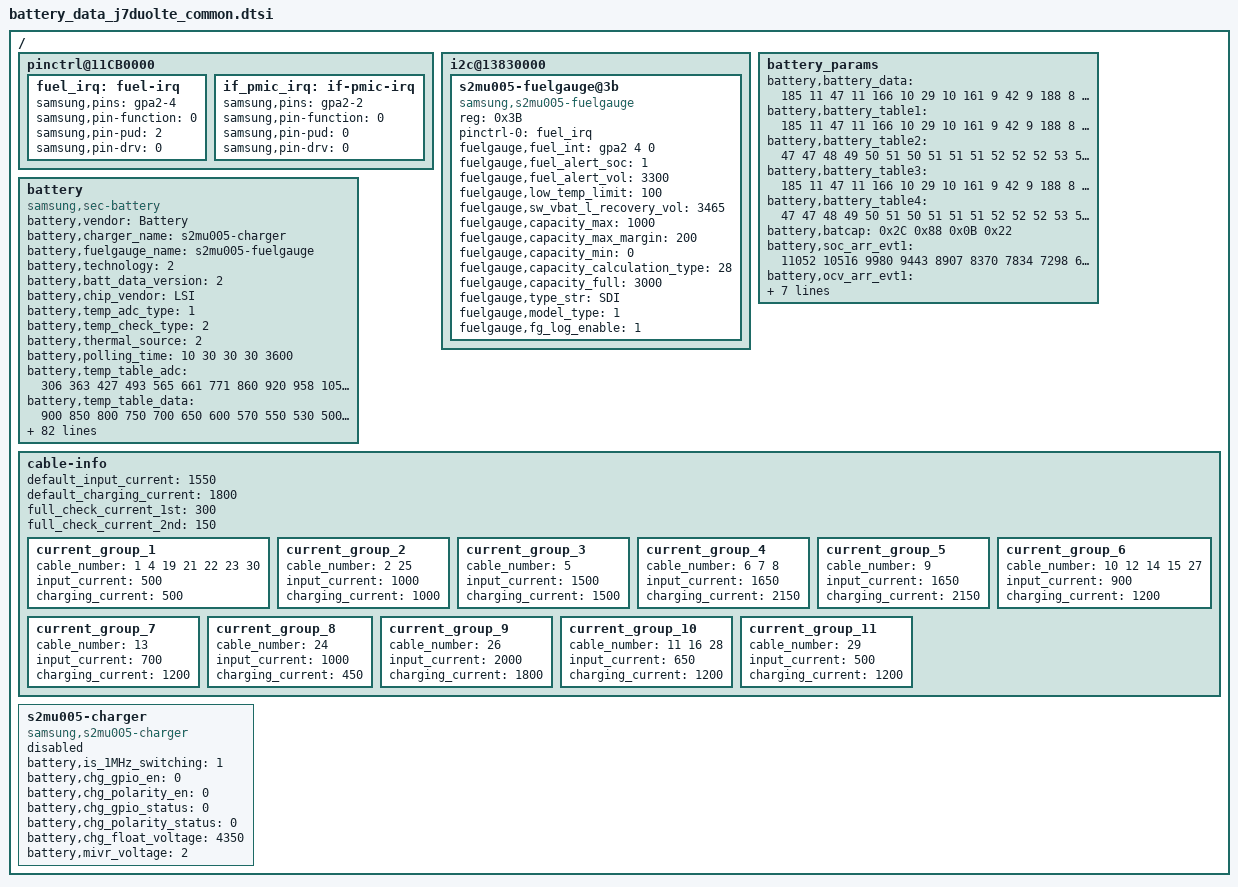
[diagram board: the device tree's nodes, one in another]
/*
 * J7 TOP Battery parameters device tree file for board IDs 04 and higher
 *
 * Copyright (C) 2017 Samsung Electronics, Inc.
 *
 * This program is free software; you can redistribute it and/or
 * modify it under the terms of the GNU General Public License
 * as published by the Free Software Foundation; either version 2
 * of the License, or (at your option) any later version.
 *
 * This program is distributed in the hope that it will be useful,
 * but WITHOUT ANY WARRANTY; without even the implied warranty of
 * MERCHANTABILITY or FITNESS FOR A PARTICULAR PURPOSE.  See the
 * GNU General Public License for more details.
 *
 * You should have received a copy of the GNU General Public License
 * along with this program. If not, see <http://www.gnu.org/licenses/>.
 *
 */

/ {
	pinctrl@11CB0000 {
		fuel_irq: fuel-irq {
			samsung,pins = "gpa2-4";
			samsung,pin-function = <0>;
			samsung,pin-pud = <2>;
			samsung,pin-drv = <0>;
		};

		if_pmic_irq: if-pmic-irq {
			samsung,pins = "gpa2-2";
			samsung,pin-function = <0>;
			samsung,pin-pud = <0>;
			samsung,pin-drv = <0>;
		};
	};

	i2c@13830000 {
		status = "okay";
		s2mu005-fuelgauge@3b {
			compatible = "samsung,s2mu005-fuelgauge";
			reg = <0x3B>;
			pinctrl-names = "default";
			pinctrl-0 = <&fuel_irq>;
			fuelgauge,fuel_int = <&gpa2 4 0>;
			fuelgauge,fuel_alert_soc = <1>;
			fuelgauge,fuel_alert_vol = <3300>;
			fuelgauge,low_temp_limit = <100>;
			fuelgauge,sw_vbat_l_recovery_vol = <3465>;
			fuelgauge,capacity_max = <1000>;
			fuelgauge,capacity_max_margin = <200>;
			fuelgauge,capacity_min = <0>;
			fuelgauge,capacity_calculation_type = <28>;
			fuelgauge,capacity_full = <3000>;
			fuelgauge,type_str = "SDI";
			fuelgauge,model_type = <1>;
			fuelgauge,fg_log_enable = <1>;
		};
	};

	battery_params {
		battery,battery_data =
			<
			/***** battery data for 4.35 *****/
			/* battery,battery_table3 */
			185 11 47 11 166 10 29 10 161 9
			42 9 188 8 87 8 230 7 155 7
			64 7 222 6 161 6 119 6 86 6
			62 6 42 6 5 6 190 5 143 5
			55 5 242 1 215 8 106 8 252 7
			142 7 32 7 178 6 68 6 215 5
			105 5 251 4 141 4 31 4 177 3
			67 3 214 2 104 2 250 1 140 1
			30 1 176 0 66 0 213 15
			
			/* battery,battery_table4 */
			47 47 48 49 50 51 50 51 51 51
			52 52 52 53 53 54 54 55 56 57
			60 150
			
			/* battery,batcap */
			0x2C 0x88 0x0B 0x22 /* [0x0F] [0x0E] [0x11] [0x10] */
			
			/* battery,accum */ 
			0x00 0x08 /* [0x44] [0x45] */
			
			/* battery,soc_arr_val */
			11052 10516 9980 9443 8907 8370 7834 7298 6761 6225
			5688 5152 4616 4079 3543 3006 2470 1933 1397 861
			324 (-212)
			
			/* battery,ocv_arr_val */
			44654 43982 43309 42642 42035 41455 40916 40427 39871 39506
			39065 38583 38285 38080 37922 37804 37704 37525 37177 36947
			36521 32432



			/***** battery data for 4.33 *****/
			/* battery,battery_table3 */
			186 11 47 11 165 10 29 10 161 9
			42 9 187 8 87 8 230 7 155 7
			64 7 222 6 161 6 119 6 86 6
			62 6 42 6 5 6 190 5 143 5
			55 5 242 1 7 9 151 8 39 8
			183 7 70 7 214 6 102 6 246 5
			134 5 21 5 165 4 53 4 197 3
			85 3 229 2 116 2 4 2 148 1
			36 1 180 0 68 0 212 15
			
			/* battery,battery_table4 */
			47 47 48 49 50 51 50 51 51 51
			52 52 52 53 53 54 54 55 56 57
			60 150
			
			/* battery,batcap */
			0x2B 0xE8 0x0A 0xFA /* [0x0F] [0x0E] [0x11] [0x10] */
			/* battery,accum */
			0x14 0x08 /* [0x44] [0x45] */
			
			/* battery,soc_arr_val */
			11285 10737 10189 9642 9094 8546 7999 7451 6903 6354
			5808 5260 4712 4165 3617 3069 2521 1974 1426 878
			331 (-217)
			/* battery,ocv_arr_val */
			44656 43982 43308 42641 42035 41454 40915 40426 39871 39506
			39065 38583 38285 38079 37922 37804 37704 37524 37177 36947
			36521 32432



			/***** battery data for 4.31 *****/
			/* battery,battery_table3 */
			185 11 47 11 166 10 29 10 161 9
			42 9 188 8 87 8 230 7 155 7
			64 7 222 6 161 6 119 6 86 6
			62 6 42 6 5 6 190 5 143 5
			55 5 242 1 48 9 190 8 76 8
			218 7 104 7 246 6 131 6 17 6
			159 5 45 5 187 4 72 4 214 3
			100 3 242 2 128 2 14 2 156 1
			41 1 183 0 69 0 211 15
			
			/* battery,battery_table4 */
			47 47 48 49 50 51 50 51 51 51
			52 52 52 53 53 54 54 55 56 57
			60 150
			
			/* battery,batcap */                                  
			0x2B 0x34 0x0A 0xCD /* [0x0F] [0x0E] [0x11] [0x10] */ 
			/* battery,accum */
			0x00 0x08 /* [0x44] [0x45] */
			
			/* battery,soc_arr_val */
			11486 10929 10371 9814 9257 8699 8142 7584 7027 6469
			5911 5354 4797 4240 3682 3125 2567 2010 1452 895
			337 (-220)
			/* battery,ocv_arr_val */
			44654 43982 43309 42641 42035 41454 40916 40427 39871 39506
			39065 38584 38286 38080 37922 37804 37704 37525 37177 36948
			36521 32432
			>;
			
			battery,battery_table1 = <
					185 11 47 11 166 10 29 10 161 9
					42 9 188 8 87 8 230 7 155 7
					64 7 222 6 161 6 119 6 86 6
					62 6 42 6 5 6 190 5 143 5
					55 5 242 1 215 8 106 8 252 7
					142 7 32 7 178 6 68 6 215 5
					105 5 251 4 141 4 31 4 177 3
					67 3 214 2 104 2 250 1 140 1
					30 1 176 0 66 0 213 15
					>;

			battery,battery_table2 = <
					47 47 48 49 50 51 50 51 51 51
					52 52 52 53 53 54 54 55 56 57
					60 150
					>;

			battery,battery_table3 = <
					185 11 47 11 166 10 29 10 161 9
					42 9 188 8 87 8 230 7 155 7
					64 7 222 6 161 6 119 6 86 6
					62 6 42 6 5 6 190 5 143 5
					55 5 242 1 215 8 106 8 252 7
					142 7 32 7 178 6 68 6 215 5
					105 5 251 4 141 4 31 4 177 3
					67 3 214 2 104 2 250 1 140 1
					30 1 176 0 66 0 213 15
					>;

			battery,battery_table4 = <
					47 47 48 49 50 51 50 51 51 51
					52 52 52 53 53 54 54 55 56 57
					60 150
					>;

			battery,batcap = <0x2C 0x88 0x0B 0x22>; /* [0x0F] [0x0E] [0x11] [0x10] */

			battery,soc_arr_evt1 = <
						11052 10516 9980 9443 8907 8370 7834 7298 6761 6225
						5688 5152 4616 4079 3543 3006 2470 1933 1397 861
						324 (-212)
						>;
			battery,ocv_arr_evt1 = <
						44654 43982 43309 42642 42035 41455 40916 40427 39871 39506
						39065 38583 38285 38080 37922 37804 37704 37525 37177 36947
						36521 32432
						>;

			battery,soc_arr_evt2 = <
						11052 10516 9980 9443 8907 8370 7834 7298 6761 6225
						5688 5152 4616 4079 3543 3006 2470 1933 1397 861
						324 (-212)
						>;
			battery,ocv_arr_evt2 = <
						44654 43982 43309 42642 42035 41455 40916 40427 39871 39506
						39065 38583 38285 38080 37922 37804 37704 37525 37177 36947
						36521 32432
						>;

			battery,FG_Accumulative_rate_evt2 = <0x00 0x08>; /* 0x44 0x45 */
			battery,data_ver = <0x03>;
	};

	battery {
		status = "okay";
		compatible = "samsung,sec-battery";

		pinctrl-names = "default";

		battery,vendor = "Battery";
		battery,charger_name = "s2mu005-charger";
		battery,fuelgauge_name = "s2mu005-fuelgauge";
		battery,technology = <2>; /* POWER_SUPPLY_TECHNOLOGY_LION */

		battery,batt_data_version = <2>;

		battery,chip_vendor = "LSI";
		battery,temp_adc_type = <1>; /* SEC_BATTERY_ADC_TYPE_AP */

		battery,temp_check_type = <2>; /* SEC_BATTERY_TEMP_CHECK_TEMP */

		battery,thermal_source = <2>; /* SEC_BATTERY_THERMAL_SOURCE_ADC */

		battery,polling_time = <10 30 30 30 3600>;

		battery,temp_table_adc = <
					306 363 427 493 565 661 771 860 920 958
					1051 1143 1210 1281 1364 1395 1459 1534 1591 1815
					2017 2241 2469 2557 2689 2780 2819 2897 2971 3083 3160
					3245 3389 3508 3603
					>;
		battery,temp_table_data = <
					900 850 800 750 700 650 600 570 550 530
					500 470 450 430 410 400 380 360 350 300
					250 200 150 130 100 80 70 50 30 0 (-30)
					(-50) (-100) (-150) (-200)
					>;

		battery,adc_check_count = <5>;

		battery,cable_check_type = <4>; /* SEC_BATTERY_CABLE_CHECK_PSY */
		battery,cable_source_type = <1>; /* SEC_BATTERY_CABLE_SOURCE_EXTERNAL */
		battery,polling_type = <1>; /* SEC_BATTERY_MONITOR_ALARM */
		battery,monitor_initial_count = <0>;

		battery,pre_afc_input_current = <500>;

		battery,battery_check_type = <5>; /* SEC_BATTERY_CHECK_CHARGER */
		battery,check_count = <0>;

		battery,ovp_uvlo_check_type = <3>; /* SEC_BATTERY_OVP_UVLO_CHGPOLLING */

		battery,temp_check_count = <1>;
		battery,temp_highlimit_threshold_event = <800>;
		battery,temp_highlimit_recovery_event = <750>;
		battery,temp_high_threshold_event = <500>;
		battery,temp_high_recovery_event = <450>;
		battery,temp_low_threshold_event = <0>;
		battery,temp_low_recovery_event = <50>;
		battery,temp_highlimit_threshold_normal = <800>;
		battery,temp_highlimit_recovery_normal = <750>;
		battery,temp_high_threshold_normal = <500>;
		battery,temp_high_recovery_normal = <450>;
		battery,temp_low_threshold_normal = <0>;
		battery,temp_low_recovery_normal = <50>;
		battery,temp_highlimit_threshold_lpm = <800>;
		battery,temp_highlimit_recovery_lpm = <750>;
		battery,temp_high_threshold_lpm = <500>;
		battery,temp_high_recovery_lpm = <450>;
		battery,temp_low_threshold_lpm = <0>;
		battery,temp_low_recovery_lpm = <50>;
		battery,wpc_high_threshold_normal = <450>;
		battery,wpc_high_recovery_normal = <400>;
		battery,wpc_low_threshold_normal = <0>;
		battery,wpc_low_recovery_normal = <50>;

		battery,full_check_type = <2>; /* SEC_BATTERY_FULLCHARGED_FG_CURRENT */
		battery,full_check_type_2nd = <2>; /* SEC_BATTERY_FULLCHARGED_FG_CURRENT */
		battery,full_check_count = <1>;
		battery,chg_gpio_full_check = <0>;
		battery,chg_polarity_full_check = <1>;

		/* SEC_BATTERY_FULL_CONDITION_SOC |
		 * SEC_BATTERY_FULL_CONDITION_NOTIMEFULL |
		 * SEC_BATTERY_FULL_CONDITION_VCELL
		 */
		battery,full_condition_type = <13>;
		battery,full_condition_soc = <93>;
		battery,full_condition_vcell = <4250>;

		battery,recharge_check_count = <1>;
		battery,recharge_condition_type = <4>; /* SEC_BATTERY_RECHARGE_CONDITION_VCELL */
		battery,recharge_condition_soc = <98>;
		battery,recharge_condition_vcell = <4280>;

		battery,charging_total_time = <14400>;
		battery,hv_charging_total_time = <10800>;
		battery,normal_charging_total_time = <18000>;
		battery,usb_charging_total_time = <36000>;
		battery,recharging_total_time = <5400>;
		battery,charging_reset_time = <0>;

		battery,chg_float_voltage = <4350>;

		battery,swelling_high_temp_block = <410>;
		battery,swelling_high_temp_recov = <390>;
		battery,swelling_wc_high_temp_recov = <390>;
		battery,swelling_low_temp_block_1st = <150>;
		battery,swelling_low_temp_recov_1st = <200>;
		battery,swelling_low_temp_block_2nd = <50>;
		battery,swelling_low_temp_recov_2nd = <100>;

		battery,swelling_low_temp_current = <750>;	/* 0.3C */
		battery,swelling_low_temp_topoff = <150>;	/* 0.05C */
		battery,swelling_high_temp_current = <1100>;	/* 0.45C */
		battery,swelling_high_temp_topoff = <150>;	/* 0.05C */
		battery,swelling_wc_high_temp_current = <750>;	/* 0.3C */
		battery,swelling_wc_low_temp_current = <750>;	/* 0.3C */

		battery,swelling_drop_float_voltage = <4150>;
		battery,swelling_high_rechg_voltage = <4000>;
		battery,swelling_low_rechg_voltage = <4000>;

		battery,siop_event_check_type = <1>;
		battery,siop_call_cv_current = <330>;
		battery,siop_call_cc_current = <330>;

		battery,siop_input_limit_current = <1200>;
		battery,siop_charging_limit_current = <1000>;

		battery,battery_full_capacity = <3000>;

		/* cycle(week), chg_float_voltage, recharge_condition_vcell, full_condition_vcell, full_condition_soc*/
		battery,age_data = <0 4350 4280 4250 93
				28 4330 4260 4230 91
				36 4310 4240 4210 89>;	

		battery,standard_curr = <1602>;
		battery,expired_time = <13800>; /* 160 + 70 minutes */
		battery,recharging_expired_time = <5400>;

		battery,cisd_max_voltage_thr = <5000>; /* battery ovp detection voltage */

		battery,recovery_cable;

		io-channels = <&exynos_adc 1>;
		io-channel-names = "adc-temp";
		#io-channel-cells = <5>;
		io-channel-ranges;

	};

/* sec_battery_cable
 *   0	UNKNOWN,
 *   1	NONE,
 *   2	PREPARE_TA,
 *   3	TA,
 *   4	USB,
 *   5	USB_CDP,
 *   6	9V_TA,
 *   7	9V_ERR,
 *   8	9V_UNKNOWN,
 *   9	12V_TA,
 *  10	WIRELESS,
 *  11	HV_WIRELESS,
 *  12	PMA_WIRELESS,
 *  13	WIRELESS_PACK,
 *  14	WIRELESS_PACK_TA,
 *  15	WIRELESS_STAND,
 *  16	WIRELESS_HV_STAND,
 *  17	QC20,
 *  18	QC30,
 *  19	PDIC,
 *  20	UARTOFF,
 *  21	OTG,
 *  22	LAN_HUB,
 *  23	POWER_SHARING,
 *  24	HMT_CONNECTED,
 *  25	HMT_CHARGE,
 *  26	HV_TA_CHG_LIMIT,
 *  27	WIRELESS_VEHICLE,
 *  28	WIRELESS_HV_VEHICLE,
 *  29	PREPARE_WIRELESS_HV,
 *  30	TIMEOUT,
 *  31	CABLE_MAX,
 */
	cable-info {
		default_input_current = <1550>;
		default_charging_current = <1800>;
		full_check_current_1st = <300>;
		full_check_current_2nd = <150>;

		current_group_1 {
			cable_number = <1 4 19 21 22 23 30>;
			input_current = <500>;
			charging_current = <500>;
		};

		current_group_2 {
			cable_number = <2 25>;
			input_current = <1000>;
			charging_current = <1000>;
		};

		current_group_3 {
			cable_number = <5>;
			input_current = <1500>;
			charging_current = <1500>;
		};

		current_group_4 {
			cable_number = <6 7 8>;
			input_current = <1650>;
			charging_current = <2150>;
		};

		current_group_5 {
			cable_number = <9>;
			input_current = <1650>;
			charging_current = <2150>;
		};

		current_group_6 {
			cable_number = <10 12 14 15 27>;
			input_current = <900>;
			charging_current = <1200>;
		};

		current_group_7 {
			cable_number = <13>;
			input_current = <700>;
			charging_current = <1200>;
		};

		current_group_8 {
			cable_number = <24>;
			input_current = <1000>;
			charging_current = <450>;
		};

		current_group_9 {
			cable_number = <26>;
			input_current = <2000>;
			charging_current = <1800>;
		};

		current_group_10 {
			cable_number = <11 16 28>;
			input_current = <650>;
			charging_current = <1200>;
		};

		current_group_11 {
			cable_number = <29>;
			input_current = <500>;
			charging_current = <1200>;
		};
	};

	s2mu005-charger {
		status = "disable";
		compatible = "samsung,s2mu005-charger";
		battery,is_1MHz_switching = <1>;
		battery,chg_gpio_en = <0>;
		battery,chg_polarity_en = <0>;
		battery,chg_gpio_status = <0>;
		battery,chg_polarity_status = <0>;
		battery,chg_float_voltage = <4350>;
		battery,mivr_voltage = <2>; /* 0:  4200, 1 : 4300, 2 : 4400 ..... 7: 4900 */
	};
};
